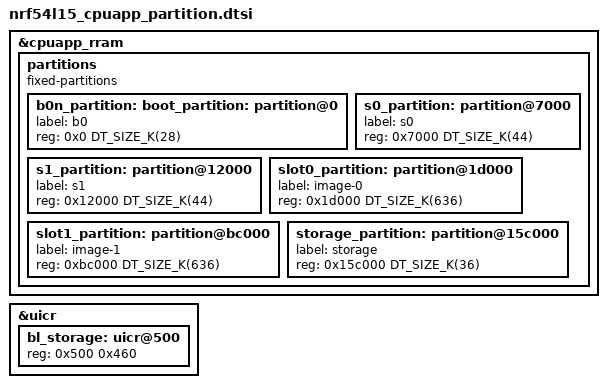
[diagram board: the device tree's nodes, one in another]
/*
 * Copyright (c) 2025 Nordic Semiconductor ASA
 *
 * SPDX-License-Identifier: Apache-2.0
 */

&cpuapp_rram {
	partitions {
		compatible = "fixed-partitions";
		#address-cells = <1>;
		#size-cells = <1>;

		b0n_partition: boot_partition: partition@0 {
			label = "b0";
			reg = <0x0 DT_SIZE_K(28)>;
		};

		s0_partition: partition@7000 {
			label = "s0";
			reg = <0x7000 DT_SIZE_K(44)>;
		};

		s1_partition: partition@12000 {
			label = "s1";
			reg = <0x12000 DT_SIZE_K(44)>;
		};

		slot0_partition: partition@1d000 {
			label = "image-0";
			reg = <0x1d000 DT_SIZE_K(636)>;
		};

		slot1_partition: partition@bc000 {
			label = "image-1";
			reg = <0xbc000 DT_SIZE_K(636)>;
		};

		storage_partition: partition@15c000 {
			label = "storage";
			reg = <0x15c000 DT_SIZE_K(36)>;
		};
	};
};

&uicr {
	bl_storage: uicr@500 {
		reg = <0x500 0x460>;
		#address-cells = <1>;
		#size-cells = <1>;
	};
};
